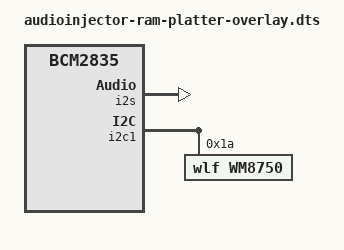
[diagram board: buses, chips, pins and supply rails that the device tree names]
// Definitions for audioinjector.net audio add on soundcard
/dts-v1/;
/plugin/;

/ {
	compatible = "brcm,bcm2835";

	fragment@0 {
		target = <&i2s>;
		__overlay__ {
			status = "okay";
		};
	};

	fragment@1 {
		target = <&i2c1>;
		__overlay__ {
			#address-cells = <1>;
			#size-cells = <0>;
			status = "okay";

			wm8750@1a {
				#sound-dai-cells = <0>;
				compatible = "wlf,wm8750";
				reg = <0x1a>;
				status = "okay";
			};
		};
	};

	fragment@2 {
		target = <&sound>;
		__overlay__ {
			compatible = "ai,audioinjector-ram-platter";
			i2s-controller = <&i2s>;
			status = "okay";
		};
	};
};
